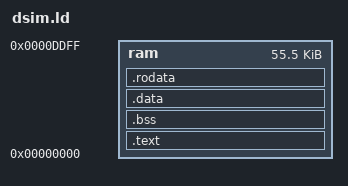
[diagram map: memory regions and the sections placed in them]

MEMORY
{
    ram : ORIGIN = 0x0000, LENGTH = 0xE000-0x0200
}
SECTIONS
{
    .text : { *(.text*) } > ram
    .bss : { *(.bss*) } > ram
    .data : { *(.data*) } > ram
    .rodata : { *(.rodata*) } > ram
}

